# NUC122_v1 register map
File version: 1.0
Registers are 32-bit, read-write, reset 0x0 unless marked. A register's access mark holds for its fields unless they carry their own. Offsets are from the block's base; [hi:lo] are bit positions.

## WDT — WDT Register Map
Base 0x40004000
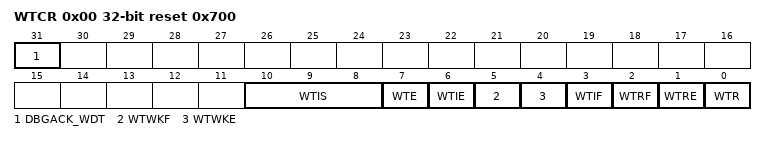
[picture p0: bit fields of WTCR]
0x00 WTCR reset 0x700 — Watchdog Timer Control Register
  [31] DBGACK_WDT — ICE Debug Mode Acknowledge Disable (write-protection bit). Watchdog Timer counter will keep going no matter CPU is held by ICE or no.
    0=ICE debug mode acknowledgement effects Watchdog Timer counting; 1=ICE debug mode acknowledgement disabled
  [10:8] WTIS — Watchdog Timer Interval Select (write-protection bits)
  [7] WTE — Watchdog Timer Enable (write-protection bit)
    0=Watchdog Timer Disabled (This action will reset the internal counter); 1=Watchdog Timer Enabled
  [6] WTIE — Watchdog Timer Interrupt Enable (write-protection bit). If this bit is enabled, the WDT time-out interrupt signal is generated and inform to CPU.
    0=Watchdog Timer interrupt Disabled; 1=Watchdog Timer interrupt Enabled
  [5] WTWKF — Watchdog Timer Wake-Up Flag. This bit indicates the interrupt wake-up flag status of WDT. Note: This bit is cleared by writing 1 to this bit.
    0=Watchdog Timer does not cause chip wake-up; 1=Chip wake-up from Idle or Power-down mode if WDT time-out interrupt signal generated
  [4] WTWKE — Watchdog Timer Wake-Up Function Enable bit (write-protection bit). If this bit is set to 1, while WDT interrupt flag (WTCR[3] WTIF) is generated to 1 and WTIE (WTCR[6] WDT interrupt enable) is enabled, the WDT time-out interrupt signal will generate a wake-up trigger event to chip. Note: Chip can be woken-up by WDT time-out interrupt signal generated only if WDT clock source is selected to 10 kHz oscillator.
    0=Wake-up trigger event Disabled if WDT time-out interrupt signal generated; 1=Wake-up trigger event Enabled if WDT time-out interrupt signal generated
  [3] WTIF — Watchdog Timer Interrupt Flag. This bit will set to 1 while WDT counter value reaches the selected WDT time-out interval. Note: This bit is cleared by writing 1 to this bit..
    0=Watchdog Timer time-out interrupt did not occur; 1=Watchdog Timer time-out interrupt occurred
  [2] WTRF — Watchdog Timer Reset Flag. This bit indicates the system has been reset by WDT time-out reset or not. Note: This bit is cleared by writing 1 to this bit.
    0=Watchdog Timer time-out reset did not occur; 1=Watchdog Timer time-out reset occurred
  [1] WTRE — Watchdog Timer Reset Enable (write-protection bit). Setting this bit will enable the Watchdog Timer time-out reset function If the WDT counter value has not been cleared after the specific WDT reset delay period expires.
    0=Watchdog Timer time-out reset function Disabled; 1=Watchdog Timer time-out reset function Enabled
  [0] WTR — Reset Watchdog Timer Counter (write-protection bit). Set this bit will reset the Watchdog Timer. Note: This bit will be automatically cleared by hardware
    0=No effect; 1=Reset the internal 18-bit WDT counter

## FMC — FMC Register Map
Base 0x5000C000
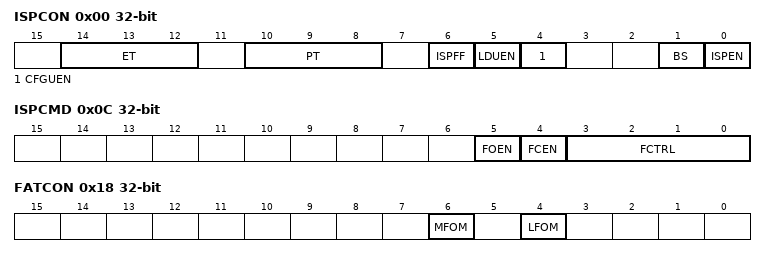
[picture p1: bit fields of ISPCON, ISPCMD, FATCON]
0x00 ISPCON — ISP Control Register
  [14:12] ET — Flash Erase Time (write-protection bits)
  [10:8] PT — Flash Program Time (write-protection bits)
  [6] ISPFF — ISP Fail Flag (write-protection bit). This bit is set by hardware when a triggered ISP meets any of the following conditions: (1) APROM writes to itself (2) LDROM writes to itself (3) CONFIG is erased/programmed if CFGUEN is set to 0 (4) Destination address is illegal, such as over an available range. Write 1 to clear.
  [5] LDUEN — LDROM Update Enable (write-protection bit). LDROM update enable bit.
    0=LDROM can not be updated; 1=LDROM can be updated when the chip runs in APROM
  [4] CFGUEN — Enable Config-bits Update by ISP (write-protection bit)
    0=Disable ISP can update config-bits; 1=Enable ISP can update config-bits
  [1] BS — Boot Select (write-protection bit). Set/clear this bit to select next booting from LDROM/APROM, respectively. This bit also functions as chip booting status flag, which can be used to check where chip booted from. This bit is initiated with the inversed value of CBS in Config0 after any reset is happened except CPU reset (RSTS_CPU is 1) or system reset (RSTS_SYS) is happened.
    0=boot from APROM; 1=boot from LDROM
  [0] ISPEN — ISP Enable (write-protection bit). ISP function enable bit. Set this bit to enable ISP function.
    0=Disable ISP function; 1=Enable ISP function
0x04 ISPADR — ISP Address Register
  [31:0] ISPADR — ISP Address. NuMicro( NUC122 Series equips with a maximum 16Kx32 embedded flash, it supports word program only. ISPADR[1:0] must be kept 00b for ISP operation.
0x08 ISPDAT — ISP Data Register
  [31:0] ISPDAT — ISP Data. Write data to this register before ISP program operation. Read data from this register after ISP read operation
0x0C ISPCMD — ISP Command Register
  [5] FOEN — ISP Command
  [4] FCEN — ISP Command
  [3:0] FCTRL — ISP Command
0x10 ISPTRG — ISP Trigger Control Register
  [0] ISPGO — ISP Start Trigger. Write 1 to start ISP operation and this bit will be cleared to 0 by hardware automatically when ISP operation is finished.
    0=ISP operation is finished; 1=ISP is on going
0x18 FATCON — Flash Access Window Control Register
  [6] MFOM — Middle Frequency Optimization Mode (write-protection bit). If chip operation frequency is between 20 MHz ~ 40 MHz, chip can work more efficiently when this bit is set to 1. If chip operation frequency is 40 MHz, both of LFOM and MFOM have to set to zero.
  [4] LFOM — Low Frequency Optimization Mode (write-protection bit). If chip operation frequency lower than 20 MHz, chip can work more efficiently when this bit is set to 1. If chip operation frequency is 40 MHz, both of LFOM and MFOM have to set to zero.
